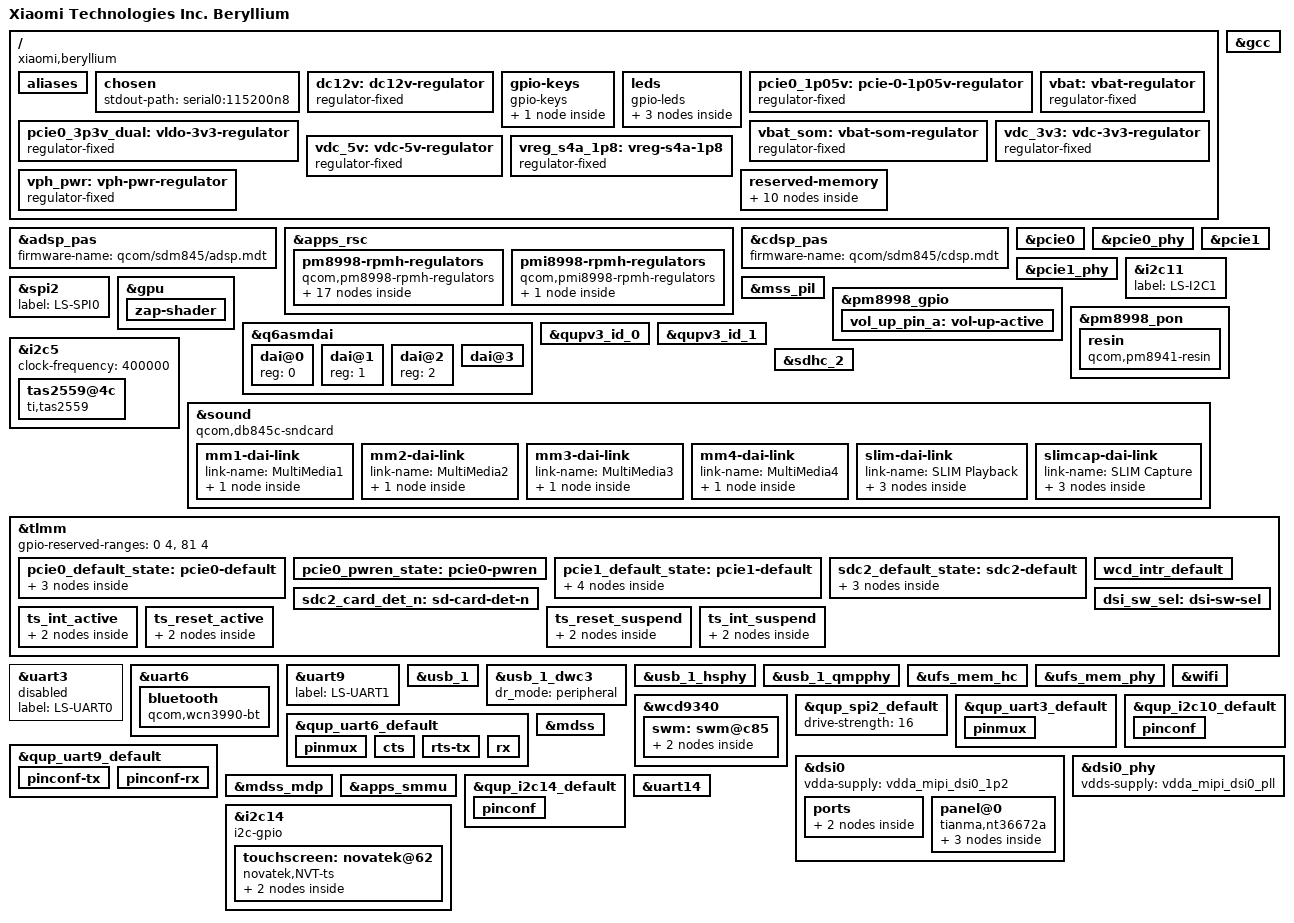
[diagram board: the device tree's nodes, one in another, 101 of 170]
// SPDX-License-Identifier: GPL-2.0

/dts-v1/;

#include <dt-bindings/gpio/gpio.h>
#include <dt-bindings/pinctrl/qcom,pmic-gpio.h>
#include <dt-bindings/regulator/qcom,rpmh-regulator.h>
#include <dt-bindings/sound/qcom,q6afe.h>
#include <dt-bindings/sound/qcom,q6asm.h>
#include "sdm845.dtsi"
#include "pm8998.dtsi"
#include "pmi8998.dtsi"

/ {
	model = "Xiaomi Technologies Inc. Beryllium";
	compatible = "xiaomi,beryllium", "qcom,sdm845";

	/* required for bootloader to select correct board */
	qcom,board-id = <69 0>;
	qcom,msm-id = <321 0x20001>;

	aliases {
		serial0 = &uart9;
		hsuart0 = &uart6;
	};

	chosen {
		stdout-path = "serial0:115200n8";
	};

	dc12v: dc12v-regulator {
		compatible = "regulator-fixed";
		regulator-name = "DC12V";
		regulator-min-microvolt = <12000000>;
		regulator-max-microvolt = <12000000>;
		regulator-always-on;
	};

	gpio-keys {
		compatible = "gpio-keys";
		autorepeat;

		pinctrl-names = "default";
		pinctrl-0 = <&vol_up_pin_a>;

		vol-up {
			label = "Volume Up";
			linux,code = <KEY_VOLUMEUP>;
			gpios = <&pm8998_gpio 6 GPIO_ACTIVE_LOW>;
		};
	};

	leds {
		compatible = "gpio-leds";

		user4 {
			label = "green:user4";
			gpios = <&pm8998_gpio 13 GPIO_ACTIVE_HIGH>;
			linux,default-trigger = "panic-indicator";
			default-state = "off";
		};

		wlan {
			label = "yellow:wlan";
			gpios = <&pm8998_gpio 9 GPIO_ACTIVE_HIGH>;
			linux,default-trigger = "phy0tx";
			default-state = "off";
		};

		bt {
			label = "blue:bt";
			gpios = <&pm8998_gpio 5 GPIO_ACTIVE_HIGH>;
			linux,default-trigger = "bluetooth-power";
			default-state = "off";
		};
	};

	pcie0_1p05v: pcie-0-1p05v-regulator {
		compatible = "regulator-fixed";
		regulator-name = "PCIE0_1.05V";

		vin-supply = <&vbat>;
		regulator-min-microvolt = <1050000>;
		regulator-max-microvolt = <1050000>;

		// TODO: make it possible to drive same GPIO from two clients
		// gpio = <&tlmm 90 GPIO_ACTIVE_HIGH>;
		// enable-active-high;
	};

	pcie0_3p3v_dual: vldo-3v3-regulator {
		compatible = "regulator-fixed";
		regulator-name = "VLDO_3V3";

		vin-supply = <&vbat>;
		regulator-min-microvolt = <3300000>;
		regulator-max-microvolt = <3300000>;

		gpio = <&tlmm 90 GPIO_ACTIVE_HIGH>;
		enable-active-high;

		pinctrl-names = "default";
		pinctrl-0 = <&pcie0_pwren_state>;
	};

	vbat: vbat-regulator {
		compatible = "regulator-fixed";
		regulator-name = "VBAT";

		vin-supply = <&dc12v>;
		regulator-min-microvolt = <4200000>;
		regulator-max-microvolt = <4200000>;
		regulator-always-on;
	};

	vbat_som: vbat-som-regulator {
		compatible = "regulator-fixed";
		regulator-name = "VBAT_SOM";

		vin-supply = <&dc12v>;
		regulator-min-microvolt = <4200000>;
		regulator-max-microvolt = <4200000>;
		regulator-always-on;
	};

	vdc_3v3: vdc-3v3-regulator {
		compatible = "regulator-fixed";
		regulator-name = "VDC_3V3";
		vin-supply = <&dc12v>;
		regulator-min-microvolt = <3300000>;
		regulator-max-microvolt = <3300000>;
		regulator-always-on;
	};

	vdc_5v: vdc-5v-regulator {
		compatible = "regulator-fixed";
		regulator-name = "VDC_5V";

		vin-supply = <&dc12v>;
		regulator-min-microvolt = <500000>;
		regulator-max-microvolt = <500000>;
		regulator-always-on;
	};

	vreg_s4a_1p8: vreg-s4a-1p8 {
		compatible = "regulator-fixed";
		regulator-name = "vreg_s4a_1p8";

		regulator-min-microvolt = <1800000>;
		regulator-max-microvolt = <1800000>;
		regulator-always-on;
	};

	vph_pwr: vph-pwr-regulator {
		compatible = "regulator-fixed";
		regulator-name = "vph_pwr";

		vin-supply = <&vbat_som>;
	};
};

&adsp_pas {
	status = "okay";
	firmware-name = "qcom/sdm845/adsp.mdt";
};

&apps_rsc {
	pm8998-rpmh-regulators {
		compatible = "qcom,pm8998-rpmh-regulators";
		qcom,pmic-id = "a";
		vdd-s1-supply = <&vph_pwr>;
		vdd-s2-supply = <&vph_pwr>;
		vdd-s3-supply = <&vph_pwr>;
		vdd-s4-supply = <&vph_pwr>;
		vdd-s5-supply = <&vph_pwr>;
		vdd-s6-supply = <&vph_pwr>;
		vdd-s7-supply = <&vph_pwr>;
		vdd-s8-supply = <&vph_pwr>;
		vdd-s9-supply = <&vph_pwr>;
		vdd-s10-supply = <&vph_pwr>;
		vdd-s11-supply = <&vph_pwr>;
		vdd-s12-supply = <&vph_pwr>;
		vdd-s13-supply = <&vph_pwr>;
		vdd-l1-l27-supply = <&vreg_s7a_1p025>;
		vdd-l2-l8-l17-supply = <&vreg_s3a_1p35>;
		vdd-l3-l11-supply = <&vreg_s7a_1p025>;
		vdd-l4-l5-supply = <&vreg_s7a_1p025>;
		vdd-l6-supply = <&vph_pwr>;
		vdd-l7-l12-l14-l15-supply = <&vreg_s5a_2p04>;
		vdd-l9-supply = <&vreg_bob>;
		vdd-l10-l23-l25-supply = <&vreg_bob>;
		vdd-l13-l19-l21-supply = <&vreg_bob>;
		vdd-l16-l28-supply = <&vreg_bob>;
		vdd-l18-l22-supply = <&vreg_bob>;
		vdd-l20-l24-supply = <&vreg_bob>;
		vdd-l26-supply = <&vreg_s3a_1p35>;
		vin-lvs-1-2-supply = <&vreg_s4a_1p8>;

		vreg_s3a_1p35: smps3 {
			regulator-min-microvolt = <1352000>;
			regulator-max-microvolt = <1352000>;
		};

		vreg_s5a_2p04: smps5 {
			regulator-min-microvolt = <1904000>;
			regulator-max-microvolt = <2040000>;
		};

		vreg_s7a_1p025: smps7 {
			regulator-min-microvolt = <900000>;
			regulator-max-microvolt = <1028000>;
		};

		vdda_mipi_dsi0_pll:
		vreg_l1a_0p875: ldo1 {
			regulator-min-microvolt = <880000>;
			regulator-max-microvolt = <880000>;
			regulator-initial-mode = <RPMH_REGULATOR_MODE_HPM>;
		};

		vreg_l5a_0p8: ldo5 {
			regulator-min-microvolt = <800000>;
			regulator-max-microvolt = <800000>;
			regulator-initial-mode = <RPMH_REGULATOR_MODE_HPM>;
		};

		vreg_l7a_1p8: ldo7 {
			regulator-min-microvolt = <1800000>;
			regulator-max-microvolt = <1800000>;
			regulator-initial-mode = <RPMH_REGULATOR_MODE_HPM>;
		};

		vreg_l12a_1p8: ldo12 {
			regulator-min-microvolt = <1800000>;
			regulator-max-microvolt = <1800000>;
			regulator-initial-mode = <RPMH_REGULATOR_MODE_HPM>;
		};

		vreg_l13a_2p95: ldo13 {
			regulator-min-microvolt = <1800000>;
			regulator-max-microvolt = <2960000>;
			regulator-initial-mode = <RPMH_REGULATOR_MODE_HPM>;
		};

		vreg_l14a_1p88: ldo14 {
			regulator-min-microvolt = <1800000>;
			regulator-max-microvolt = <1800000>;
			regulator-initial-mode = <RPMH_REGULATOR_MODE_HPM>;
			regulator-boot-on;
			regulator-always-on;
                };

		vreg_l17a_1p3: ldo17 {
			regulator-min-microvolt = <1304000>;
			regulator-max-microvolt = <1304000>;
			regulator-initial-mode = <RPMH_REGULATOR_MODE_HPM>;
		};

		vreg_l20a_2p95: ldo20 {
			regulator-min-microvolt = <2960000>;
			regulator-max-microvolt = <2968000>;
			regulator-initial-mode = <RPMH_REGULATOR_MODE_HPM>;
		};

		vreg_l21a_2p95: ldo21 {
			regulator-min-microvolt = <2960000>;
			regulator-max-microvolt = <2968000>;
			regulator-initial-mode = <RPMH_REGULATOR_MODE_HPM>;
		};

		vreg_l24a_3p075: ldo24 {
			regulator-min-microvolt = <3088000>;
			regulator-max-microvolt = <3088000>;
			regulator-initial-mode = <RPMH_REGULATOR_MODE_HPM>;
		};

		vreg_l25a_3p3: ldo25 {
			regulator-min-microvolt = <3300000>;
			regulator-max-microvolt = <3312000>;
			regulator-initial-mode = <RPMH_REGULATOR_MODE_HPM>;
		};

		vdda_mipi_dsi0_1p2:
		vreg_l26a_1p2: ldo26 {
			regulator-min-microvolt = <1200000>;
			regulator-max-microvolt = <1200000>;
			regulator-initial-mode = <RPMH_REGULATOR_MODE_HPM>;
			regulator-boot-on;
		};

		vreg_lvs1a_1p8: lvs1 {
			regulator-min-microvolt = <1800000>;
			regulator-max-microvolt = <1800000>;
			regulator-always-on;
		};

		vreg_lvs2a_1p8: lvs2 {
			regulator-min-microvolt = <1800000>;
			regulator-max-microvolt = <1800000>;
			regulator-always-on;
		};
	};

	pmi8998-rpmh-regulators {
		compatible = "qcom,pmi8998-rpmh-regulators";
		qcom,pmic-id = "b";

		vdd-bob-supply = <&vph_pwr>;

		vreg_bob: bob {
			regulator-min-microvolt = <3312000>;
			regulator-max-microvolt = <3600000>;
			regulator-initial-mode = <RPMH_REGULATOR_MODE_AUTO>;
			regulator-allow-bypass;
		};
	};
};

&cdsp_pas {
	status = "okay";
	firmware-name = "qcom/sdm845/cdsp.mdt";
};

&gcc {
	protected-clocks = <GCC_QSPI_CORE_CLK>,
			   <GCC_QSPI_CORE_CLK_SRC>,
			   <GCC_QSPI_CNOC_PERIPH_AHB_CLK>,
			   <GCC_LPASS_Q6_AXI_CLK>,
			   <GCC_LPASS_SWAY_CLK>;
};

&pcie0 {
	status = "okay";
	perst-gpio = <&tlmm 35 GPIO_ACTIVE_LOW>;
	enable-gpio = <&tlmm 134 GPIO_ACTIVE_HIGH>;

	vddpe-3v3-supply = <&pcie0_3p3v_dual>;

	pinctrl-names = "default";
	pinctrl-0 = <&pcie0_default_state>;
};

&pcie0_phy {
	status = "okay";

	vdda-phy-supply = <&vreg_l1a_0p875>;
	vdda-pll-supply = <&vreg_l26a_1p2>;
};

&pcie1 {
	status = "okay";
	perst-gpio = <&tlmm 102 GPIO_ACTIVE_LOW>;

	pinctrl-names = "default";
	pinctrl-0 = <&pcie1_default_state>;
};

&pcie1_phy {
	status = "okay";

	vdda-phy-supply = <&vreg_l1a_0p875>;
	vdda-pll-supply = <&vreg_l26a_1p2>;
};

&i2c11 {
	/* On Low speed expansion */
	label = "LS-I2C1";
	status = "okay";
};

&spi2 {
	/* On Low speed expansion */
	label = "LS-SPI0";
	status = "okay";
};

&gpu {
	zap-shader {
		memory-region = <&gpu_mem>;
		firmware-name = "qcom/sdm845/a630_zap.mbn";
	};
};

/* Reserved memory changes from downstream */
/delete-node/ &adsp_mem;
/delete-node/ &wlan_msa_mem;
/delete-node/ &mpss_region;
/delete-node/ &venus_mem;
/delete-node/ &cdsp_mem;
/delete-node/ &mba_region;
/delete-node/ &slpi_mem;
/delete-node/ &spss_mem;
/delete-node/ &rmtfs_mem;
/ {
	reserved-memory {
		// This removed_region is needed to boot the device
		// TODO: Find out the user of this reserved memory
		removed_region: memory@88f00000 {
			reg = <0 0x88f00000 0 0x1a00000>;
			no-map;
		};

		adsp_mem: memory@8c500000 {
			reg = <0 0x8c500000 0 0x1e00000>;
			no-map;
		};

		wlan_msa_mem: memory@8e300000 {
			reg = <0 0x8e300000 0 0x100000>;
			no-map;
		};

		mpss_region: memory@8e400000 {
			reg = <0 0x8e400000 0 0x7800000>;
			no-map;
		};

		venus_mem: memory@95c00000 {
			reg = <0 0x95c00000 0 0x500000>;
			no-map;
		};

		cdsp_mem: memory@96100000 {
			reg = <0 0x96100000 0 0x800000>;
			no-map;
		};

		mba_region: memory@96900000 {
			reg = <0 0x96900000 0 0x200000>;
			no-map;
		};

		slpi_mem: memory@96b00000 {
			reg = <0 0x96b00000 0 0x1400000>;
			no-map;
		};

		spss_mem: memory@97f00000 {
			reg = <0 0x97f00000 0 0x100000>;
			no-map;
		};

		rmtfs_mem: memory@f6301000 {
			compatible = "qcom,rmtfs-mem";
			reg = <0 0xf6301000 0 0x200000>;
			no-map;

			qcom,client-id = <1>;
			qcom,vmid = <15>;
		};
	};
};

&mss_pil {
	status = "okay";
	firmware-name = "qcom/sdm845/mba.mbn", "qcom/sdm845/modem.mdt";
};

&pcie0 {
	status = "okay";
	perst-gpio = <&tlmm 35 GPIO_ACTIVE_LOW>;
	enable-gpio = <&tlmm 134 GPIO_ACTIVE_HIGH>;

	vddpe-3v3-supply = <&pcie0_3p3v_dual>;

	pinctrl-names = "default";
	pinctrl-0 = <&pcie0_default_state>;
};

&pcie0_phy {
	status = "okay";

	vdda-phy-supply = <&vreg_l1a_0p875>;
	vdda-pll-supply = <&vreg_l26a_1p2>;
};

&pcie1 {
	status = "okay";
	perst-gpio = <&tlmm 102 GPIO_ACTIVE_LOW>;

	pinctrl-names = "default";
	pinctrl-0 = <&pcie1_default_state>;
};

&pcie1_phy {
	status = "okay";

	vdda-phy-supply = <&vreg_l1a_0p875>;
	vdda-pll-supply = <&vreg_l26a_1p2>;
};

&pm8998_gpio {
	vol_up_pin_a: vol-up-active {
		pins = "gpio6";
		function = "normal";
		input-enable;
		bias-pull-up;
		qcom,drive-strength = <PMIC_GPIO_STRENGTH_NO>;
	};
};

&pm8998_pon {
	resin {
		compatible = "qcom,pm8941-resin";
		interrupts = <0x0 0x8 1 IRQ_TYPE_EDGE_BOTH>;
		debounce = <15625>;
		bias-pull-up;
		linux,code = <KEY_VOLUMEDOWN>;
	};
};

&q6asmdai {
	dai@0 {
		reg = <0>;
	};

	dai@1 {
		reg = <1>;
	};

	dai@2 {
		reg = <2>;
	};

	dai@3 {
		reg = <3>;
		direction = <2>;
		is-compress-dai;
	};
};

&qupv3_id_0 {
	status = "okay";
};

&qupv3_id_1 {
	status = "okay";
};

&i2c5 {
	status="okay";
	clock-frequency = <400000>;

       /*smart PA*/
       tas2559@4c{
               compatible = "ti,tas2559";
               reg = <0x4c>;
               ti,tas2559-reset-gpio = <&tlmm 12 0>;
               ti,tas2560-reset-gpio = <&tlmm 76 0>;
               ti,tas2559-irq-gpio = <&tlmm 11 0>;
               ti,tas2560-irq-gpio = <&tlmm 30 0>;
               ti,tas2559-addr = <0x4c>;
               ti,tas2560-addr = <0x4d>;
               ti,tas2559-channel = <0>; /* 0, left; 1, right */
               ti,tas2560-channel = <1>; /* 0, left; 1, right */
               ti,ycrc-enable = <1>;           /* 0, disable; non-zero, enable */
               ti,echo-ref = <0>;              /* 0, left channel; 1, right channel; 2, both */
               ti,bit-rate = <16>;             /* 16, 20, 24, 32 */
               status = "okay";
       };

};

&sdhc_2 {
	status = "okay";

	pinctrl-names = "default";
	pinctrl-0 = <&sdc2_default_state &sdc2_card_det_n>;

	vmmc-supply = <&vreg_l21a_2p95>;
	vqmmc-supply = <&vreg_l13a_2p95>;

	bus-width = <4>;
	cd-gpios = <&tlmm 126 GPIO_ACTIVE_HIGH>;
};

&sound {
	compatible = "qcom,db845c-sndcard";
	pinctrl-0 = <&quat_mi2s_active
			 &quat_mi2s_sd0_active
			 &quat_mi2s_sd1_active
			 &quat_mi2s_sd2_active
			 &quat_mi2s_sd3_active>;
	pinctrl-names = "default";
	model = "Xiaomi Poco F1";
	audio-routing =
		"RX_BIAS", "MCLK",
		"AMIC1", "MIC BIAS1",
		"AMIC2", "MIC BIAS2",
		"DMIC0", "MIC BIAS1",
		"DMIC1", "MIC BIAS1",
		"DMIC2", "MIC BIAS3",
		"DMIC3", "MIC BIAS3",
		"SpkrLeft IN", "SPK1 OUT",
		"SpkrRight IN", "SPK2 OUT",
		"MM_DL1",  "MultiMedia1 Playback",
		"MM_DL2",  "MultiMedia2 Playback",
		"MM_DL4",  "MultiMedia4 Playback",
		"MultiMedia2 Capture", "MM_UL2",
		"MultiMedia3 Capture", "MM_UL3";

	mm1-dai-link {
		link-name = "MultiMedia1";
		cpu {
			sound-dai = <&q6asmdai  MSM_FRONTEND_DAI_MULTIMEDIA1>;
		};
	};

	mm2-dai-link {
		link-name = "MultiMedia2";
		cpu {
			sound-dai = <&q6asmdai  MSM_FRONTEND_DAI_MULTIMEDIA2>;
		};
	};

	mm3-dai-link {
		link-name = "MultiMedia3";
		cpu {
			sound-dai = <&q6asmdai  MSM_FRONTEND_DAI_MULTIMEDIA3>;
		};
	};

	mm4-dai-link {
		link-name = "MultiMedia4";
		cpu {
			sound-dai = <&q6asmdai  MSM_FRONTEND_DAI_MULTIMEDIA4>;
		};
	};

	slim-dai-link {
		link-name = "SLIM Playback";
		cpu {
			sound-dai = <&q6afedai SLIMBUS_0_RX>;
		};

		platform {
			sound-dai = <&q6routing>;
		};

		codec {
			sound-dai =  <&left_spkr>, <&right_spkr>, <&swm 0>, <&wcd9340 0>;
		};
	};

	slimcap-dai-link {
		link-name = "SLIM Capture";
		cpu {
			sound-dai = <&q6afedai SLIMBUS_0_TX>;
		};

		platform {
			sound-dai = <&q6routing>;
		};

		codec {
			sound-dai = <&wcd9340 1>;
		};
	};
};

&spi2 {
	/* On Low speed expansion */
	label = "LS-SPI0";
	status = "okay";
};

&tlmm {
	gpio-reserved-ranges = <0 4>, <81 4>;

	pcie0_default_state: pcie0-default {
		clkreq {
			pins = "gpio36";
			function = "pci_e0";
			bias-pull-up;
		};

		reset-n {
			pins = "gpio35";
			function = "gpio";

			drive-strength = <2>;
			output-low;
			bias-pull-down;
		};

		wake-n {
			pins = "gpio37";
			function = "gpio";

			drive-strength = <2>;
			bias-pull-up;
		};
	};

	pcie0_pwren_state: pcie0-pwren {
		pins = "gpio90";
		function = "gpio";

		drive-strength = <2>;
		bias-disable;
	};

	pcie1_default_state: pcie1-default {
		perst-n {
			pins = "gpio102";
			function = "gpio";

			drive-strength = <16>;
			bias-disable;
		};

		clkreq {
			pins = "gpio103";
			function = "pci_e1";
			bias-pull-up;
		};

		wake-n {
			pins = "gpio11";
			function = "gpio";

			drive-strength = <2>;
			bias-pull-up;
		};

		reset-n {
			pins = "gpio75";
			function = "gpio";

			drive-strength = <16>;
			bias-pull-up;
			output-high;
		};
	};

	sdc2_default_state: sdc2-default {
		clk {
			pins = "sdc2_clk";
			bias-disable;

			/*
			 * It seems that mmc_test reports errors if drive
			 * strength is not 16 on clk, cmd, and data pins.
			 */
			drive-strength = <16>;
		};

		cmd {
			pins = "sdc2_cmd";
			bias-pull-up;
			drive-strength = <10>;
		};

		data {
			pins = "sdc2_data";
			bias-pull-up;
			drive-strength = <10>;
		};
	};

	sdc2_card_det_n: sd-card-det-n {
		pins = "gpio126";
		function = "gpio";
		bias-pull-up;
	};

	wcd_intr_default: wcd_intr_default {
		pins = <54>;
		function = "gpio";

		input-enable;
		bias-pull-down;
		drive-strength = <2>;
	};

	dsi_sw_sel: dsi-sw-sel {
		pins = "gpio120";
		function = "gpio";

		drive-strength = <2>;
		bias-disable;
		output-high;
	};

	ts_int_active: ts_int_active {
		mux {
			pins = "gpio31";
			function = "gpio";
		};

		config {
			pins = "gpio31";
			drive-strength = <16>;
			bias-pull-down;
			input-enable;
		};
	};

	ts_reset_active: ts_reset_active {
		mux {
			pins = "gpio32";
			function = "gpio";
		};

		config {
			pins = "gpio32";
			drive-strength = <16>;
			output-high;
		};
	};

	ts_reset_suspend: ts_reset_suspend {
		mux {
			pins = "gpio32";
			function = "gpio";
		};

		config {
			pins = "gpio32";
			drive-strength = <2>;
			bias-disable;
			output-low;
		};
	};

	ts_int_suspend: ts_int_suspend {
		mux {
			pins = "gpio31";
			function = "gpio";
		};

		config {
			pins = "gpio31";
			drive-strength = <2>;
			bias-pull-down;
			input-enable;
		};
	};
};

&uart3 {
	label = "LS-UART0";
	status = "disabled";
};

&uart6 {
	status = "okay";

	bluetooth {
		compatible = "qcom,wcn3990-bt";

		vddio-supply = <&vreg_s4a_1p8>;
		vddxo-supply = <&vreg_l7a_1p8>;
		vddrf-supply = <&vreg_l17a_1p3>;
		vddch0-supply = <&vreg_l25a_3p3>;
		max-speed = <3200000>;
	};
};

&uart9 {
	label = "LS-UART1";
	status = "okay";
};

&usb_1 {
	status = "okay";
};

&usb_1_dwc3 {
	dr_mode = "peripheral";
};

&usb_1_hsphy {
	status = "okay";

	vdd-supply = <&vreg_l1a_0p875>;
	vdda-pll-supply = <&vreg_l12a_1p8>;
	vdda-phy-dpdm-supply = <&vreg_l24a_3p075>;

	qcom,imp-res-offset-value = <8>;
	qcom,hstx-trim-value = <QUSB2_V2_HSTX_TRIM_21_6_MA>;
	qcom,preemphasis-level = <QUSB2_V2_PREEMPHASIS_5_PERCENT>;
	qcom,preemphasis-width = <QUSB2_V2_PREEMPHASIS_WIDTH_HALF_BIT>;
};

&usb_1_qmpphy {
	status = "okay";

	vdda-phy-supply = <&vreg_l26a_1p2>;
	vdda-pll-supply = <&vreg_l1a_0p875>;
};

&ufs_mem_hc {
	status = "okay";

	reset-gpios = <&tlmm 150 GPIO_ACTIVE_LOW>;

	vcc-supply = <&vreg_l20a_2p95>;
	vcc-max-microamp = <800000>;
};

&ufs_mem_phy {
	status = "okay";

	vdda-phy-supply = <&vreg_l1a_0p875>;
	vdda-pll-supply = <&vreg_l26a_1p2>;
};

&wcd9340{
	pinctrl-0 = <&wcd_intr_default>;
	pinctrl-names = "default";
	clock-names = "extclk";
	clocks = <&rpmhcc RPMH_LN_BB_CLK2>;
	reset-gpios = <&tlmm 64 0>;
	vdd-buck-supply = <&vreg_s4a_1p8>;
	vdd-buck-sido-supply = <&vreg_s4a_1p8>;
	vdd-tx-supply = <&vreg_s4a_1p8>;
	vdd-rx-supply = <&vreg_s4a_1p8>;
	vdd-io-supply = <&vreg_s4a_1p8>;

	swm: swm@c85 {
		left_spkr: wsa8810-left{
			compatible = "sdw10217201000";
			reg = <0 1>;
			powerdown-gpios = <&wcdgpio 2 GPIO_ACTIVE_HIGH>;
			#thermal-sensor-cells = <0>;
			sound-name-prefix = "SpkrLeft";
			#sound-dai-cells = <0>;
		};

		right_spkr: wsa8810-right{
			compatible = "sdw10217201000";
			powerdown-gpios = <&wcdgpio 2 GPIO_ACTIVE_HIGH>;
			reg = <0 2>;
			#thermal-sensor-cells = <0>;
			sound-name-prefix = "SpkrRight";
			#sound-dai-cells = <0>;
		};
	};
};

&wifi {
	status = "okay";

	vdd-0.8-cx-mx-supply = <&vreg_l5a_0p8>;
	vdd-1.8-xo-supply = <&vreg_l7a_1p8>;
	vdd-1.3-rfa-supply = <&vreg_l17a_1p3>;
	vdd-3.3-ch0-supply = <&vreg_l25a_3p3>;
};

/* PINCTRL - additions to nodes defined in sdm845.dtsi */
&qup_spi2_default {
	drive-strength = <16>;
};

&qup_uart3_default{
	pinmux {
		pins = "gpio41", "gpio42", "gpio43", "gpio44";
		function = "qup3";
	};
};

&qup_i2c10_default {
	pinconf {
		pins = "gpio55", "gpio56";
		drive-strength = <2>;
		bias-disable;
	};
};

&qup_uart6_default {
	pinmux {
		pins = "gpio45", "gpio46", "gpio47", "gpio48";
		function = "qup6";
	};

	cts {
		pins = "gpio45";
		bias-disable;
	};

	rts-tx {
		pins = "gpio46", "gpio47";
		drive-strength = <2>;
		bias-disable;
	};

	rx {
		pins = "gpio48";
		bias-pull-up;
	};
};

&qup_uart9_default {
	pinconf-tx {
		pins = "gpio4";
		drive-strength = <2>;
		bias-disable;
	};

	pinconf-rx {
		pins = "gpio5";
		drive-strength = <2>;
		bias-pull-up;
	};
};

&dsi0 {
	status = "okay";
	vdda-supply = <&vdda_mipi_dsi0_1p2>;

	ports {
		port@1 {
			endpoint {
				remote-endpoint = <&tianma_nt36672a_in_0>;
				data-lanes = <0 1 2 3>;
			};
		};
	};

	panel@0 {
		compatible = "tianma,nt36672a";
		reg = <0>;
		vddi0-supply = <&vreg_l14a_1p88>;
		vddpos-supply = <&lab>;
		vddneg-supply = <&ibb>;

		reset-gpios = <&tlmm 6 GPIO_ACTIVE_HIGH>;

		pinctrl-names = "panel_active", "panel_suspend";
		pinctrl-0 = <&sde_dsi_active>;
		pinctrl-1 = <&sde_dsi_suspend>;

		ports {
			#address-cells = <1>;
			#size-cells = <0>;

			port@0 {
				reg = <0>;
				tianma_nt36672a_in_0: endpoint {
					remote-endpoint = <&dsi0_out>;
				};
			};
		};
	};
};

&dsi0_phy {
	status = "okay";
	vdds-supply = <&vdda_mipi_dsi0_pll>;
};

&mdss {
	status = "okay";
};

&mdss_mdp {
	status = "okay";
};

&apps_smmu {

	status = "okay";

};

&qup_i2c14_default{
        pinconf {
                pins = "gpio33", "gpio34";
                drive-strength = <2>;
                bias-pull-up;
        };
};

&i2c14 {
	compatible = "i2c-gpio";

        status="okay";

	sda-gpios = <&tlmm 33 (GPIO_ACTIVE_HIGH|GPIO_OPEN_DRAIN)>;
	scl-gpios = <&tlmm 34 (GPIO_ACTIVE_HIGH|GPIO_OPEN_DRAIN)>;
	i2c-gpio,delay-us = <5>;	/* 5~=100 kHz */ /* could probably run on higher speeds */
	#address-cells = <1>;
	#size-cells = <0>;

        touchscreen: novatek@62 {
                compatible = "novatek,NVT-ts";
                reg = <0x62>;
                status = "okay";

                vddio-supply = <&vreg_l14a_1p88>;
//                avdd-supply = <&pm8994_l22>;
                lab-supply = <&lab>;
                ibb-supply = <&ibb>;
                novatek,vddio-reg-name = "vddio";
                novatek,lab-reg-name = "lab";
                novatek,ibb-reg-name = "ibb";

                novatek,reset-tddi = <&tlmm 6 0x00 /* GPIO_ACTIVE_HIGH */ >;
                novatek,reset-gpio = <&tlmm 32 0x00 /* GPIO_ACTIVE_HIGH */ >;
                novatek,irq-gpio = <&tlmm 31 0x2001>;
//		enable-active-high;

                pinctrl-names = "pmx_ts_active", "pmx_ts_suspend";
                pinctrl-0 = <&ts_int_active &ts_reset_active>;
                pinctrl-1 = <&ts_int_suspend &ts_reset_suspend>;
                novatek,config-array-size = <2>;
                novatek,dump-click-count;
                novatek,cfg_0 {
                        novatek,tp-vendor = <0x46>;
                        novatek,hw-version = <0x1>;
                        novatek,fw-name = "novatek_nt36672_e10_hw01.fw";
//                      novatek,clicknum-file-name = "nvt+tianma";
                };
                novatek,cfg_1 {
                        novatek,tp-vendor = <0x46>;
                        novatek,hw-version = <0x2>;
                        novatek,fw-name = "novatek_nt36672_e10_hw02.fw";
//                      novatek,clicknum-file-name = "nvt+tianma";
                };
        };

};

&uart14 {

        status = "okay";

};
